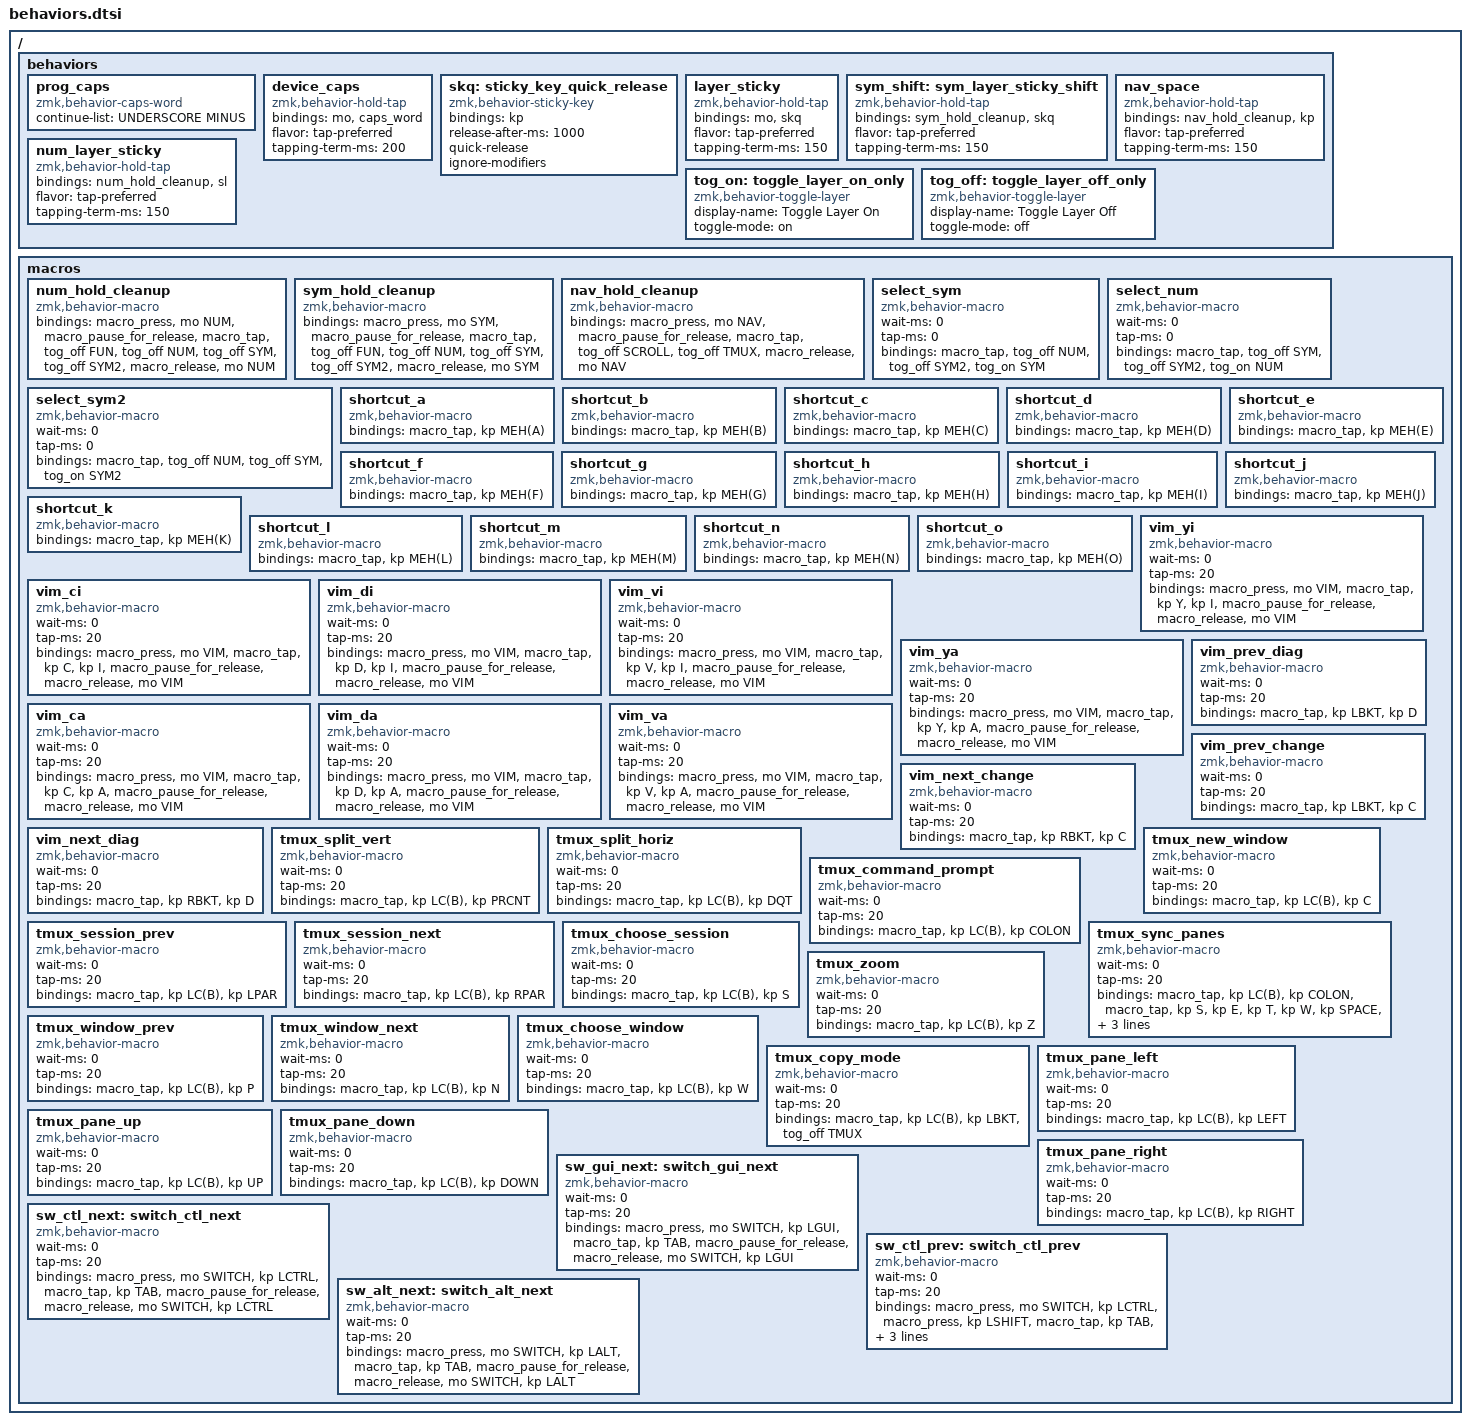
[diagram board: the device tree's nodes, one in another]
#define HYPER LC(LA(LS(LGUI)))
#define SGUI LS(LGUI)
#define SCTL LS(LCTRL)
#define SALT LS(LALT)
#define MEH(keycode) LC(LA(LS(keycode)))

/ {
    behaviors {
        prog_caps: prog_caps {
            compatible = "zmk,behavior-caps-word";
            #binding-cells = <0>;
            continue-list = <UNDERSCORE MINUS>;
        };

        device_caps: device_caps {
            compatible = "zmk,behavior-hold-tap";
            #binding-cells = <2>;
            bindings = <&mo>, <&caps_word>;
            flavor = "tap-preferred";
            tapping-term-ms = <200>;
        };

        skq: sticky_key_quick_release {
            compatible = "zmk,behavior-sticky-key";
            #binding-cells = <1>;
            bindings = <&kp>;
            release-after-ms = <1000>;
            quick-release;
            ignore-modifiers;
        };

        layer_sticky: layer_sticky {
            compatible = "zmk,behavior-hold-tap";
            #binding-cells = <2>;
            bindings = <&mo>, <&skq>;
            flavor = "tap-preferred";
            tapping-term-ms = <150>;
        };

        sym_shift: sym_layer_sticky_shift {
            compatible = "zmk,behavior-hold-tap";
            #binding-cells = <2>;
            bindings = <&sym_hold_cleanup>, <&skq>;
            flavor = "tap-preferred";
            tapping-term-ms = <150>;
        };

        nav_space: nav_space {
            compatible = "zmk,behavior-hold-tap";
            #binding-cells = <2>;
            bindings = <&nav_hold_cleanup>, <&kp>;
            flavor = "tap-preferred";
            tapping-term-ms = <150>;
        };

        num_layer_sticky: num_layer_sticky {
            compatible = "zmk,behavior-hold-tap";
            #binding-cells = <2>;
            bindings = <&num_hold_cleanup>, <&sl>;
            flavor = "tap-preferred";
            tapping-term-ms = <150>;
        };

        tog_on: toggle_layer_on_only {
            compatible = "zmk,behavior-toggle-layer";
            #binding-cells = <1>;
            display-name = "Toggle Layer On";
            toggle-mode = "on";
        };

        tog_off: toggle_layer_off_only {
            compatible = "zmk,behavior-toggle-layer";
            #binding-cells = <1>;
            display-name = "Toggle Layer Off";
            toggle-mode = "off";
        };
    };

    macros {
        num_hold_cleanup: num_hold_cleanup {
            compatible = "zmk,behavior-macro";
            #binding-cells = <0>;
            bindings
                = <&macro_press &mo NUM>
                , <&macro_pause_for_release>
                , <&macro_tap &tog_off FUN &tog_off NUM &tog_off SYM &tog_off SYM2>
                , <&macro_release &mo NUM>
                ;
        };

        sym_hold_cleanup: sym_hold_cleanup {
            compatible = "zmk,behavior-macro";
            #binding-cells = <0>;
            bindings
                = <&macro_press &mo SYM>
                , <&macro_pause_for_release>
                , <&macro_tap &tog_off FUN &tog_off NUM &tog_off SYM &tog_off SYM2>
                , <&macro_release &mo SYM>
                ;
        };

        nav_hold_cleanup: nav_hold_cleanup {
            compatible = "zmk,behavior-macro";
            #binding-cells = <0>;
            bindings
                = <&macro_press &mo NAV>
                , <&macro_pause_for_release>
                , <&macro_tap &tog_off SCROLL &tog_off TMUX>
                , <&macro_release &mo NAV>
                ;
        };

        // Replace the active number/symbol layer without changing other layers.
        select_sym: select_sym {
            compatible = "zmk,behavior-macro";
            #binding-cells = <0>;
            wait-ms = <0>;
            tap-ms = <0>;
            bindings = <&macro_tap &tog_off NUM &tog_off SYM2 &tog_on SYM>;
        };

        select_num: select_num {
            compatible = "zmk,behavior-macro";
            #binding-cells = <0>;
            wait-ms = <0>;
            tap-ms = <0>;
            bindings = <&macro_tap &tog_off SYM &tog_off SYM2 &tog_on NUM>;
        };

        select_sym2: select_sym2 {
            compatible = "zmk,behavior-macro";
            #binding-cells = <0>;
            wait-ms = <0>;
            tap-ms = <0>;
            bindings = <&macro_tap &tog_off NUM &tog_off SYM &tog_on SYM2>;
        };

        shortcut_a: shortcut_a {
            compatible = "zmk,behavior-macro";
            #binding-cells = <0>;
            bindings = <&macro_tap &kp MEH(A)>;
        };

        shortcut_b: shortcut_b {
            compatible = "zmk,behavior-macro";
            #binding-cells = <0>;
            bindings = <&macro_tap &kp MEH(B)>;
        };

        shortcut_c: shortcut_c {
            compatible = "zmk,behavior-macro";
            #binding-cells = <0>;
            bindings = <&macro_tap &kp MEH(C)>;
        };

        shortcut_d: shortcut_d {
            compatible = "zmk,behavior-macro";
            #binding-cells = <0>;
            bindings = <&macro_tap &kp MEH(D)>;
        };

        shortcut_e: shortcut_e {
            compatible = "zmk,behavior-macro";
            #binding-cells = <0>;
            bindings = <&macro_tap &kp MEH(E)>;
        };

        shortcut_f: shortcut_f {
            compatible = "zmk,behavior-macro";
            #binding-cells = <0>;
            bindings = <&macro_tap &kp MEH(F)>;
        };

        shortcut_g: shortcut_g {
            compatible = "zmk,behavior-macro";
            #binding-cells = <0>;
            bindings = <&macro_tap &kp MEH(G)>;
        };

        shortcut_h: shortcut_h {
            compatible = "zmk,behavior-macro";
            #binding-cells = <0>;
            bindings = <&macro_tap &kp MEH(H)>;
        };

        shortcut_i: shortcut_i {
            compatible = "zmk,behavior-macro";
            #binding-cells = <0>;
            bindings = <&macro_tap &kp MEH(I)>;
        };

        shortcut_j: shortcut_j {
            compatible = "zmk,behavior-macro";
            #binding-cells = <0>;
            bindings = <&macro_tap &kp MEH(J)>;
        };

        shortcut_k: shortcut_k {
            compatible = "zmk,behavior-macro";
            #binding-cells = <0>;
            bindings = <&macro_tap &kp MEH(K)>;
        };

        shortcut_l: shortcut_l {
            compatible = "zmk,behavior-macro";
            #binding-cells = <0>;
            bindings = <&macro_tap &kp MEH(L)>;
        };

        shortcut_m: shortcut_m {
            compatible = "zmk,behavior-macro";
            #binding-cells = <0>;
            bindings = <&macro_tap &kp MEH(M)>;
        };

        shortcut_n: shortcut_n {
            compatible = "zmk,behavior-macro";
            #binding-cells = <0>;
            bindings = <&macro_tap &kp MEH(N)>;
        };

        shortcut_o: shortcut_o {
            compatible = "zmk,behavior-macro";
            #binding-cells = <0>;
            bindings = <&macro_tap &kp MEH(O)>;
        };

        vim_yi: vim_yi {
            compatible = "zmk,behavior-macro";
            #binding-cells = <0>;
            wait-ms = <0>;
            tap-ms = <20>;
            bindings
                = <&macro_press &mo VIM>
                , <&macro_tap &kp Y &kp I>
                , <&macro_pause_for_release>
                , <&macro_release &mo VIM>
                ;
        };

        vim_ci: vim_ci {
            compatible = "zmk,behavior-macro";
            #binding-cells = <0>;
            wait-ms = <0>;
            tap-ms = <20>;
            bindings
                = <&macro_press &mo VIM>
                , <&macro_tap &kp C &kp I>
                , <&macro_pause_for_release>
                , <&macro_release &mo VIM>
                ;
        };

        vim_di: vim_di {
            compatible = "zmk,behavior-macro";
            #binding-cells = <0>;
            wait-ms = <0>;
            tap-ms = <20>;
            bindings
                = <&macro_press &mo VIM>
                , <&macro_tap &kp D &kp I>
                , <&macro_pause_for_release>
                , <&macro_release &mo VIM>
                ;
        };

        vim_vi: vim_vi {
            compatible = "zmk,behavior-macro";
            #binding-cells = <0>;
            wait-ms = <0>;
            tap-ms = <20>;
            bindings
                = <&macro_press &mo VIM>
                , <&macro_tap &kp V &kp I>
                , <&macro_pause_for_release>
                , <&macro_release &mo VIM>
                ;
        };

        vim_ya: vim_ya {
            compatible = "zmk,behavior-macro";
            #binding-cells = <0>;
            wait-ms = <0>;
            tap-ms = <20>;
            bindings
                = <&macro_press &mo VIM>
                , <&macro_tap &kp Y &kp A>
                , <&macro_pause_for_release>
                , <&macro_release &mo VIM>
                ;
        };

        vim_ca: vim_ca {
            compatible = "zmk,behavior-macro";
            #binding-cells = <0>;
            wait-ms = <0>;
            tap-ms = <20>;
            bindings
                = <&macro_press &mo VIM>
                , <&macro_tap &kp C &kp A>
                , <&macro_pause_for_release>
                , <&macro_release &mo VIM>
                ;
        };

        vim_da: vim_da {
            compatible = "zmk,behavior-macro";
            #binding-cells = <0>;
            wait-ms = <0>;
            tap-ms = <20>;
            bindings
                = <&macro_press &mo VIM>
                , <&macro_tap &kp D &kp A>
                , <&macro_pause_for_release>
                , <&macro_release &mo VIM>
                ;
        };

        vim_va: vim_va {
            compatible = "zmk,behavior-macro";
            #binding-cells = <0>;
            wait-ms = <0>;
            tap-ms = <20>;
            bindings
                = <&macro_press &mo VIM>
                , <&macro_tap &kp V &kp A>
                , <&macro_pause_for_release>
                , <&macro_release &mo VIM>
                ;
        };

        vim_prev_diag: vim_prev_diag {
            compatible = "zmk,behavior-macro";
            #binding-cells = <0>;
            wait-ms = <0>;
            tap-ms = <20>;
            bindings = <&macro_tap &kp LBKT &kp D>;
        };

        vim_prev_change: vim_prev_change {
            compatible = "zmk,behavior-macro";
            #binding-cells = <0>;
            wait-ms = <0>;
            tap-ms = <20>;
            bindings = <&macro_tap &kp LBKT &kp C>;
        };

        vim_next_change: vim_next_change {
            compatible = "zmk,behavior-macro";
            #binding-cells = <0>;
            wait-ms = <0>;
            tap-ms = <20>;
            bindings = <&macro_tap &kp RBKT &kp C>;
        };

        vim_next_diag: vim_next_diag {
            compatible = "zmk,behavior-macro";
            #binding-cells = <0>;
            wait-ms = <0>;
            tap-ms = <20>;
            bindings = <&macro_tap &kp RBKT &kp D>;
        };

        tmux_split_vert: tmux_split_vert {
            compatible = "zmk,behavior-macro";
            #binding-cells = <0>;
            wait-ms = <0>;
            tap-ms = <20>;
            bindings = <&macro_tap &kp LC(B) &kp PRCNT>;
        };

        tmux_split_horiz: tmux_split_horiz {
            compatible = "zmk,behavior-macro";
            #binding-cells = <0>;
            wait-ms = <0>;
            tap-ms = <20>;
            bindings = <&macro_tap &kp LC(B) &kp DQT>;
        };

        tmux_new_window: tmux_new_window {
            compatible = "zmk,behavior-macro";
            #binding-cells = <0>;
            wait-ms = <0>;
            tap-ms = <20>;
            bindings = <&macro_tap &kp LC(B) &kp C>;
        };

        tmux_command_prompt: tmux_command_prompt {
            compatible = "zmk,behavior-macro";
            #binding-cells = <0>;
            wait-ms = <0>;
            tap-ms = <20>;
            bindings = <&macro_tap &kp LC(B) &kp COLON>;
        };

        tmux_session_prev: tmux_session_prev {
            compatible = "zmk,behavior-macro";
            #binding-cells = <0>;
            wait-ms = <0>;
            tap-ms = <20>;
            bindings = <&macro_tap &kp LC(B) &kp LPAR>;
        };

        tmux_session_next: tmux_session_next {
            compatible = "zmk,behavior-macro";
            #binding-cells = <0>;
            wait-ms = <0>;
            tap-ms = <20>;
            bindings = <&macro_tap &kp LC(B) &kp RPAR>;
        };

        tmux_choose_session: tmux_choose_session {
            compatible = "zmk,behavior-macro";
            #binding-cells = <0>;
            wait-ms = <0>;
            tap-ms = <20>;
            bindings = <&macro_tap &kp LC(B) &kp S>;
        };

        tmux_sync_panes: tmux_sync_panes {
            compatible = "zmk,behavior-macro";
            #binding-cells = <0>;
            wait-ms = <0>;
            tap-ms = <20>;
            bindings
                = <&macro_tap &kp LC(B) &kp COLON>
                , <&macro_tap &kp S &kp E &kp T &kp W &kp SPACE &kp S &kp Y &kp N &kp C &kp H &kp R &kp O &kp N &kp I &kp Z &kp E &kp MINUS &kp P &kp A &kp N &kp E &kp S &kp ENTER>
                ;
        };

        tmux_zoom: tmux_zoom {
            compatible = "zmk,behavior-macro";
            #binding-cells = <0>;
            wait-ms = <0>;
            tap-ms = <20>;
            bindings = <&macro_tap &kp LC(B) &kp Z>;
        };

        tmux_window_prev: tmux_window_prev {
            compatible = "zmk,behavior-macro";
            #binding-cells = <0>;
            wait-ms = <0>;
            tap-ms = <20>;
            bindings = <&macro_tap &kp LC(B) &kp P>;
        };

        tmux_window_next: tmux_window_next {
            compatible = "zmk,behavior-macro";
            #binding-cells = <0>;
            wait-ms = <0>;
            tap-ms = <20>;
            bindings = <&macro_tap &kp LC(B) &kp N>;
        };

        tmux_choose_window: tmux_choose_window {
            compatible = "zmk,behavior-macro";
            #binding-cells = <0>;
            wait-ms = <0>;
            tap-ms = <20>;
            bindings = <&macro_tap &kp LC(B) &kp W>;
        };

        tmux_copy_mode: tmux_copy_mode {
            compatible = "zmk,behavior-macro";
            #binding-cells = <0>;
            wait-ms = <0>;
            tap-ms = <20>;
            bindings = <&macro_tap &kp LC(B) &kp LBKT &tog_off TMUX>;
        };

        tmux_pane_left: tmux_pane_left {
            compatible = "zmk,behavior-macro";
            #binding-cells = <0>;
            wait-ms = <0>;
            tap-ms = <20>;
            bindings = <&macro_tap &kp LC(B) &kp LEFT>;
        };

        tmux_pane_up: tmux_pane_up {
            compatible = "zmk,behavior-macro";
            #binding-cells = <0>;
            wait-ms = <0>;
            tap-ms = <20>;
            bindings = <&macro_tap &kp LC(B) &kp UP>;
        };

        tmux_pane_down: tmux_pane_down {
            compatible = "zmk,behavior-macro";
            #binding-cells = <0>;
            wait-ms = <0>;
            tap-ms = <20>;
            bindings = <&macro_tap &kp LC(B) &kp DOWN>;
        };

        tmux_pane_right: tmux_pane_right {
            compatible = "zmk,behavior-macro";
            #binding-cells = <0>;
            wait-ms = <0>;
            tap-ms = <20>;
            bindings = <&macro_tap &kp LC(B) &kp RIGHT>;
        };

        sw_gui_next: switch_gui_next {
            compatible = "zmk,behavior-macro";
            #binding-cells = <0>;
            wait-ms = <0>;
            tap-ms = <20>;
            bindings
                = <&macro_press &mo SWITCH &kp LGUI>
                , <&macro_tap &kp TAB>
                , <&macro_pause_for_release>
                , <&macro_release &mo SWITCH &kp LGUI>
                ;
        };

        sw_ctl_next: switch_ctl_next {
            compatible = "zmk,behavior-macro";
            #binding-cells = <0>;
            wait-ms = <0>;
            tap-ms = <20>;
            bindings
                = <&macro_press &mo SWITCH &kp LCTRL>
                , <&macro_tap &kp TAB>
                , <&macro_pause_for_release>
                , <&macro_release &mo SWITCH &kp LCTRL>
                ;
        };

        sw_ctl_prev: switch_ctl_prev {
            compatible = "zmk,behavior-macro";
            #binding-cells = <0>;
            wait-ms = <0>;
            tap-ms = <20>;
            bindings
                = <&macro_press &mo SWITCH &kp LCTRL>
                , <&macro_press &kp LSHIFT>
                , <&macro_tap &kp TAB>
                , <&macro_release &kp LSHIFT>
                , <&macro_pause_for_release>
                , <&macro_release &mo SWITCH &kp LCTRL>
                ;
        };

        sw_alt_next: switch_alt_next {
            compatible = "zmk,behavior-macro";
            #binding-cells = <0>;
            wait-ms = <0>;
            tap-ms = <20>;
            bindings
                = <&macro_press &mo SWITCH &kp LALT>
                , <&macro_tap &kp TAB>
                , <&macro_pause_for_release>
                , <&macro_release &mo SWITCH &kp LALT>
                ;
        };

    };
};
